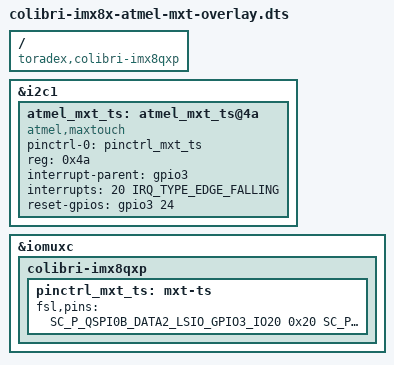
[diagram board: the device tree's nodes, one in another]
// Atmel MXT touchscreen for the 7inch and 10inch display orderable at Toradex.

/dts-v1/;
/plugin/;

#include "dt-bindings/interrupt-controller/irq.h"
#include "dt-bindings/gpio/gpio.h"
#include "dt-bindings/pinctrl/pads-imx8qxp.h"

/ {
	compatible = "toradex,colibri-imx8qxp";

	fragment@0 {
		target = <&i2c1>;
		__overlay__ {
			/* Atmel maxtouch controller */
			atmel_mxt_ts: atmel_mxt_ts@4a {
				compatible = "atmel,maxtouch";
				pinctrl-names = "default";
				pinctrl-0 = <&pinctrl_mxt_ts>;
				reg = <0x4a>;
				interrupt-parent = <&gpio3>;
				interrupts = <20 IRQ_TYPE_EDGE_FALLING>;	/* SODIMM 107 */
				reset-gpios = <&gpio3 24 GPIO_ACTIVE_HIGH>;	/* SODIMM 106 */
				status = "okay";
			};
		};
	};

	fragment@1 {
		target = <&iomuxc>;
		__overlay__ {
			colibri-imx8qxp {
				pinctrl_mxt_ts: mxt-ts {
					fsl,pins = <
						SC_P_QSPI0B_DATA2_LSIO_GPIO3_IO20		0x20		/* SODIMM 107 */
						SC_P_QSPI0B_SS1_B_LSIO_GPIO3_IO24		0x20		/* SODIMM 106 */
					>;
				};
			};
		};
	};
};
